# ATSAME51J18A register map
Vendor: Microchip Technology; Series: SAME51; File version: 0
CPU: CM4 r0p1, selectable endian, MPU, FPU, 3 interrupt priority bits
Registers are 32-bit, read-write, reset 0x0 unless marked. A register's access mark holds for its fields unless they carry their own. Offsets are from the block's base; [hi:lo] are bit positions; lines under a group give offsets from that group; {n}, {i} and the like mark numbered series; 'fields as' and 'values as' point back to an identical list.

## OSCCTRL — Oscillators Control
Base 0x40001000; register names take the prefix OSCCTRL_
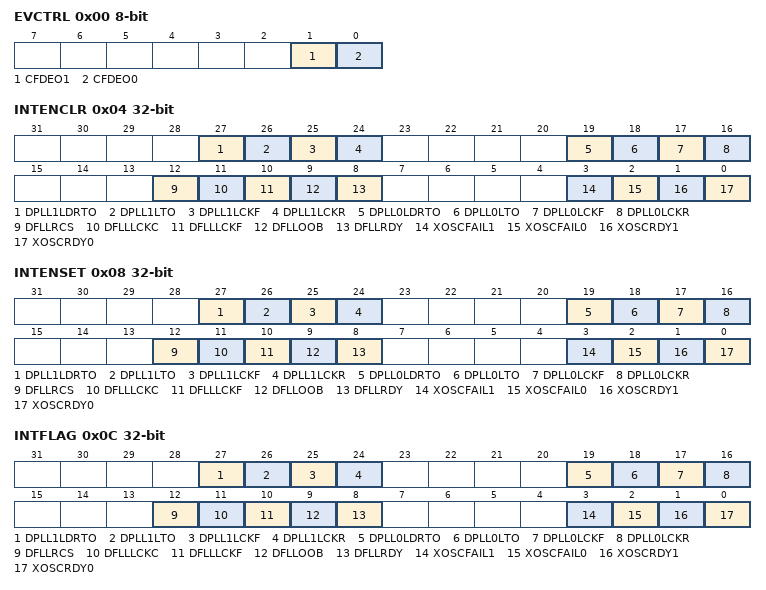
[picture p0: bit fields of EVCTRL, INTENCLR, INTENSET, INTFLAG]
0x00 EVCTRL 8-bit — Event Control
  [1] CFDEO1 — Clock 1 Failure Detector Event Output Enable
  [0] CFDEO0 — Clock 0 Failure Detector Event Output Enable
0x04 INTENCLR — Interrupt Enable Clear
  [27] DPLL1LDRTO — DPLL1 Loop Divider Ratio Update Complete Interrupt Enable
  [26] DPLL1LTO — DPLL1 Lock Timeout Interrupt Enable
  [25] DPLL1LCKF — DPLL1 Lock Fall Interrupt Enable
  [24] DPLL1LCKR — DPLL1 Lock Rise Interrupt Enable
  [19] DPLL0LDRTO — DPLL0 Loop Divider Ratio Update Complete Interrupt Enable
  [18] DPLL0LTO — DPLL0 Lock Timeout Interrupt Enable
  [17] DPLL0LCKF — DPLL0 Lock Fall Interrupt Enable
  [16] DPLL0LCKR — DPLL0 Lock Rise Interrupt Enable
  [12] DFLLRCS — DFLL Reference Clock Stopped Interrupt Enable
  [11] DFLLLCKC — DFLL Lock Coarse Interrupt Enable
  [10] DFLLLCKF — DFLL Lock Fine Interrupt Enable
  [9] DFLLOOB — DFLL Out Of Bounds Interrupt Enable
  [8] DFLLRDY — DFLL Ready Interrupt Enable
  [3] XOSCFAIL1 — XOSC 1 Clock Failure Detector Interrupt Enable
  [2] XOSCFAIL0 — XOSC 0 Clock Failure Detector Interrupt Enable
  [1] XOSCRDY1 — XOSC 1 Ready Interrupt Enable
  [0] XOSCRDY0 — XOSC 0 Ready Interrupt Enable
0x08 INTENSET — Interrupt Enable Set
  fields as INTENCLR
0x0C INTFLAG — Interrupt Flag Status and Clear
  [27] DPLL1LDRTO write-1-clears — DPLL1 Loop Divider Ratio Update Complete
  [26] DPLL1LTO write-1-clears — DPLL1 Lock Timeout
  [25] DPLL1LCKF write-1-clears — DPLL1 Lock Fall
  [24] DPLL1LCKR write-1-clears — DPLL1 Lock Rise
  [19] DPLL0LDRTO write-1-clears — DPLL0 Loop Divider Ratio Update Complete
  [18] DPLL0LTO write-1-clears — DPLL0 Lock Timeout
  [17] DPLL0LCKF write-1-clears — DPLL0 Lock Fall
  [16] DPLL0LCKR write-1-clears — DPLL0 Lock Rise
  [12] DFLLRCS write-1-clears — DFLL Reference Clock Stopped
  [11] DFLLLCKC write-1-clears — DFLL Lock Coarse
  [10] DFLLLCKF write-1-clears — DFLL Lock Fine
  [9] DFLLOOB write-1-clears — DFLL Out Of Bounds
  [8] DFLLRDY write-1-clears — DFLL Ready
  [3] XOSCFAIL1 write-1-clears — XOSC 1 Clock Failure Detector
  [2] XOSCFAIL0 write-1-clears — XOSC 0 Clock Failure Detector
  [1] XOSCRDY1 write-1-clears — XOSC 1 Ready
  [0] XOSCRDY0 write-1-clears — XOSC 0 Ready
0x10 STATUS ro
  [27] DPLL1LDRTO — DPLL1 Loop Divider Ratio Update Complete
  [26] DPLL1TO — DPLL1 Timeout
  [25] DPLL1LCKF — DPLL1 Lock Fall
  [24] DPLL1LCKR — DPLL1 Lock Rise
  [19] DPLL0LDRTO — DPLL0 Loop Divider Ratio Update Complete
  [18] DPLL0TO — DPLL0 Timeout
  [17] DPLL0LCKF — DPLL0 Lock Fall
  [16] DPLL0LCKR — DPLL0 Lock Rise
  [12] DFLLRCS — DFLL Reference Clock Stopped
  [11] DFLLLCKC — DFLL Lock Coarse
  [10] DFLLLCKF — DFLL Lock Fine
  [9] DFLLOOB — DFLL Out Of Bounds
  [8] DFLLRDY — DFLL Ready
  [5] XOSCCKSW1 — XOSC 1 Clock Switch
  [4] XOSCCKSW0 — XOSC 0 Clock Switch
  [3] XOSCFAIL1 — XOSC 1 Clock Failure Detector
  [2] XOSCFAIL0 — XOSC 0 Clock Failure Detector
  [1] XOSCRDY1 — XOSC 1 Ready
  [0] XOSCRDY0 — XOSC 0 Ready
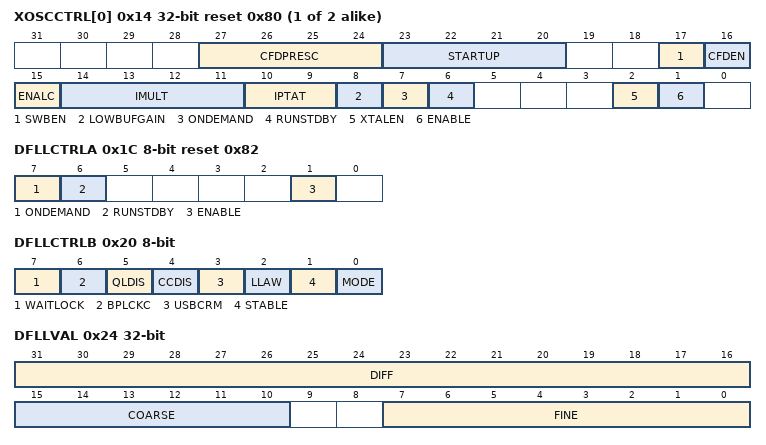
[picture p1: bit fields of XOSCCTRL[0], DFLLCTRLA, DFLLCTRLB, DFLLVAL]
{0x14+4i} XOSCCTRL[{i}] (i=0..1) reset 0x80 — External Multipurpose Crystal Oscillator Control
  [27:24] CFDPRESC — Clock Failure Detector Prescaler
    0=DIV1 (48 MHz); 1=DIV2 (24 MHz); 2=DIV4 (12 MHz); 3=DIV8 (6 MHz); 4=DIV16 (3 MHz); 5=DIV32 (1.5 MHz); 6=DIV64 (0.75 MHz); 7=DIV128 (0.3125 MHz)
  [23:20] STARTUP — Start-Up Time
    0=CYCLE1 (31 us); 1=CYCLE2 (61 us); 2=CYCLE4 (122 us); 3=CYCLE8 (244 us); 4=CYCLE16 (488 us); 5=CYCLE32 (977 us); 6=CYCLE64 (1953 us); 7=CYCLE128 (3906 us); 8=CYCLE256 (7813 us); 9=CYCLE512 (15625 us); 10=CYCLE1024 (31250 us); 11=CYCLE2048 (62500 us); 12=CYCLE4096 (125000 us); 13=CYCLE8192 (250000 us); 14=CYCLE16384 (500000 us); 15=CYCLE32768 (1000000 us)
  [17] SWBEN — Xosc Clock Switch Enable
  [16] CFDEN — Clock Failure Detector Enable
  [15] ENALC — Automatic Loop Control Enable
  [14:11] IMULT — Oscillator Current Multiplier
  [10:9] IPTAT — Oscillator Current Reference
  [8] LOWBUFGAIN — Low Buffer Gain Enable
  [7] ONDEMAND — On Demand Control
  [6] RUNSTDBY — Run in Standby
  [2] XTALEN — Crystal Oscillator Enable
  [1] ENABLE — Oscillator Enable
0x1C DFLLCTRLA 8-bit reset 0x82 — DFLL48M Control A
  [7] ONDEMAND — On Demand Control
  [6] RUNSTDBY — Run in Standby
  [1] ENABLE — DFLL Enable
0x20 DFLLCTRLB 8-bit — DFLL48M Control B
  [7] WAITLOCK
  [6] BPLCKC — Bypass Coarse Lock
  [5] QLDIS — Quick Lock Disable
  [4] CCDIS — Chill Cycle Disable
  [3] USBCRM — USB Clock Recovery Mode
  [2] LLAW — Lose Lock After Wake
  [1] STABLE — Stable DFLL Frequency
  [0] MODE — Operating Mode Selection
0x24 DFLLVAL — DFLL48M Value
  [31:16] DIFF — Multiplication Ratio Difference
  [15:10] COARSE — Coarse Value
  [7:0] FINE — Fine Value
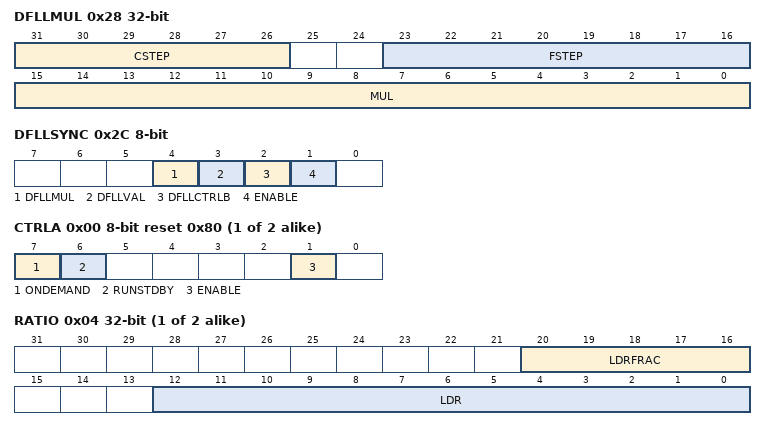
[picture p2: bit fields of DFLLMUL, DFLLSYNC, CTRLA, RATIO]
0x28 DFLLMUL — DFLL48M Multiplier
  [31:26] CSTEP — Coarse Maximum Step
  [23:16] FSTEP — Fine Maximum Step
  [15:0] MUL — DFLL Multiply Factor
0x2C DFLLSYNC 8-bit — DFLL48M Synchronization
  [4] DFLLMUL — DFLLMUL Synchronization Busy
  [3] DFLLVAL — DFLLVAL Synchronization Busy
  [2] DFLLCTRLB — DFLLCTRLB Synchronization Busy
  [1] ENABLE — ENABLE Synchronization Busy
{0x30+0x14*i} DPLL[{i}] (i=0..1) group
  0x00 CTRLA 8-bit reset 0x80 — DPLL Control A
    [7] ONDEMAND — On Demand Control
    [6] RUNSTDBY — Run in Standby
    [1] ENABLE — DPLL Enable
  0x04 RATIO — DPLL Ratio Control
    [20:16] LDRFRAC — Loop Divider Ratio Fractional Part
    [12:0] LDR — Loop Divider Ratio
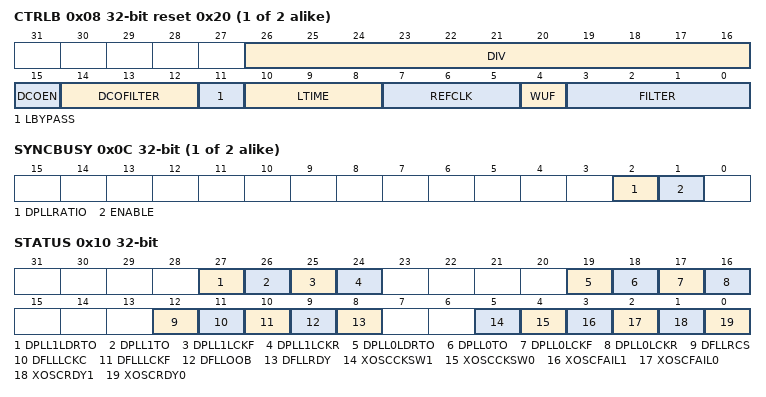
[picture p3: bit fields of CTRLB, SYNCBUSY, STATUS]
  0x08 CTRLB reset 0x20 — DPLL Control B
    [26:16] DIV — Clock Divider
    [15] DCOEN — DCO Filter Enable
    [14:12] DCOFILTER — Sigma-Delta DCO Filter Selection
      0=FILTER1 (Capacitor(pF) = 0.5 and Bandwidth Fn (MHz) = 3.21); 1=FILTER2 (Capacitor(pF) = 1 and Bandwidth Fn (MHz) = 1.6); 2=FILTER3 (Capacitor(pF) = 1.5 and Bandwidth Fn (MHz) = 1.1); 3=FILTER4 (Capacitor(pF) = 2 and Bandwidth Fn (MHz) = 0.8); 4=FILTER5 (Capacitor(pF) = 2.5 and Bandwidth Fn (MHz) = 0.64); 5=FILTER6 (Capacitor(pF) = 3 and Bandwidth Fn (MHz) = 0.55); 6=FILTER7 (Capacitor(pF) = 3.5 and Bandwidth Fn (MHz) = 0.45); 7=FILTER8 (Capacitor(pF) = 4 and Bandwidth Fn (MHz) = 0.4)
    [11] LBYPASS — Lock Bypass
    [10:8] LTIME — Lock Time
      0=DEFAULT (No time-out. Automatic lock); 4=800US (Time-out if no lock within 800us); 5=900US (Time-out if no lock within 900us); 6=1MS (Time-out if no lock within 1ms); 7=1P1MS (Time-out if no lock within 1.1ms)
    [7:5] REFCLK — Reference Clock Selection
      0=GCLK (Dedicated GCLK clock reference); 1=XOSC32 (XOSC32K clock reference); 2=XOSC0 (XOSC0 clock reference); 3=XOSC1 (XOSC1 clock reference)
    [4] WUF — Wake Up Fast
    [3:0] FILTER — Proportional Integral Filter Selection
      0=Bandwidth = 92.7Khz and Damping Factor = 0.76; 1=Bandwidth = 131Khz and Damping Factor = 1.08; 2=Bandwidth = 46.4Khz and Damping Factor = 0.38; 3=Bandwidth = 65.6Khz and Damping Factor = 0.54; 4=Bandwidth = 131Khz and Damping Factor = 0.56; 5=Bandwidth = 185Khz and Damping Factor = 0.79; 6=Bandwidth = 65.6Khz and Damping Factor = 0.28; 7=Bandwidth = 92.7Khz and Damping Factor = 0.39; 8=Bandwidth = 46.4Khz and Damping Factor = 1.49; 9=Bandwidth = 65.6Khz and Damping Factor = 2.11; 10=Bandwidth = 23.2Khz and Damping Factor = 0.75; 11=Bandwidth = 32.8Khz and Damping Factor = 1.06; 12=Bandwidth = 65.6Khz and Damping Factor = 1.07; 13=Bandwidth = 92.7Khz and Damping Factor = 1.51; 14=Bandwidth = 32.8Khz and Damping Factor = 0.53; 15=Bandwidth = 46.4Khz and Damping Factor = 0.75
  0x0C SYNCBUSY ro — DPLL Synchronization Busy
    [2] DPLLRATIO — DPLL Loop Divider Ratio Synchronization Status
    [1] ENABLE — DPLL Enable Synchronization Status
  0x10 STATUS ro — DPLL Status
    [1] CLKRDY — DPLL Clock Ready
    [0] LOCK — DPLL Lock Status
